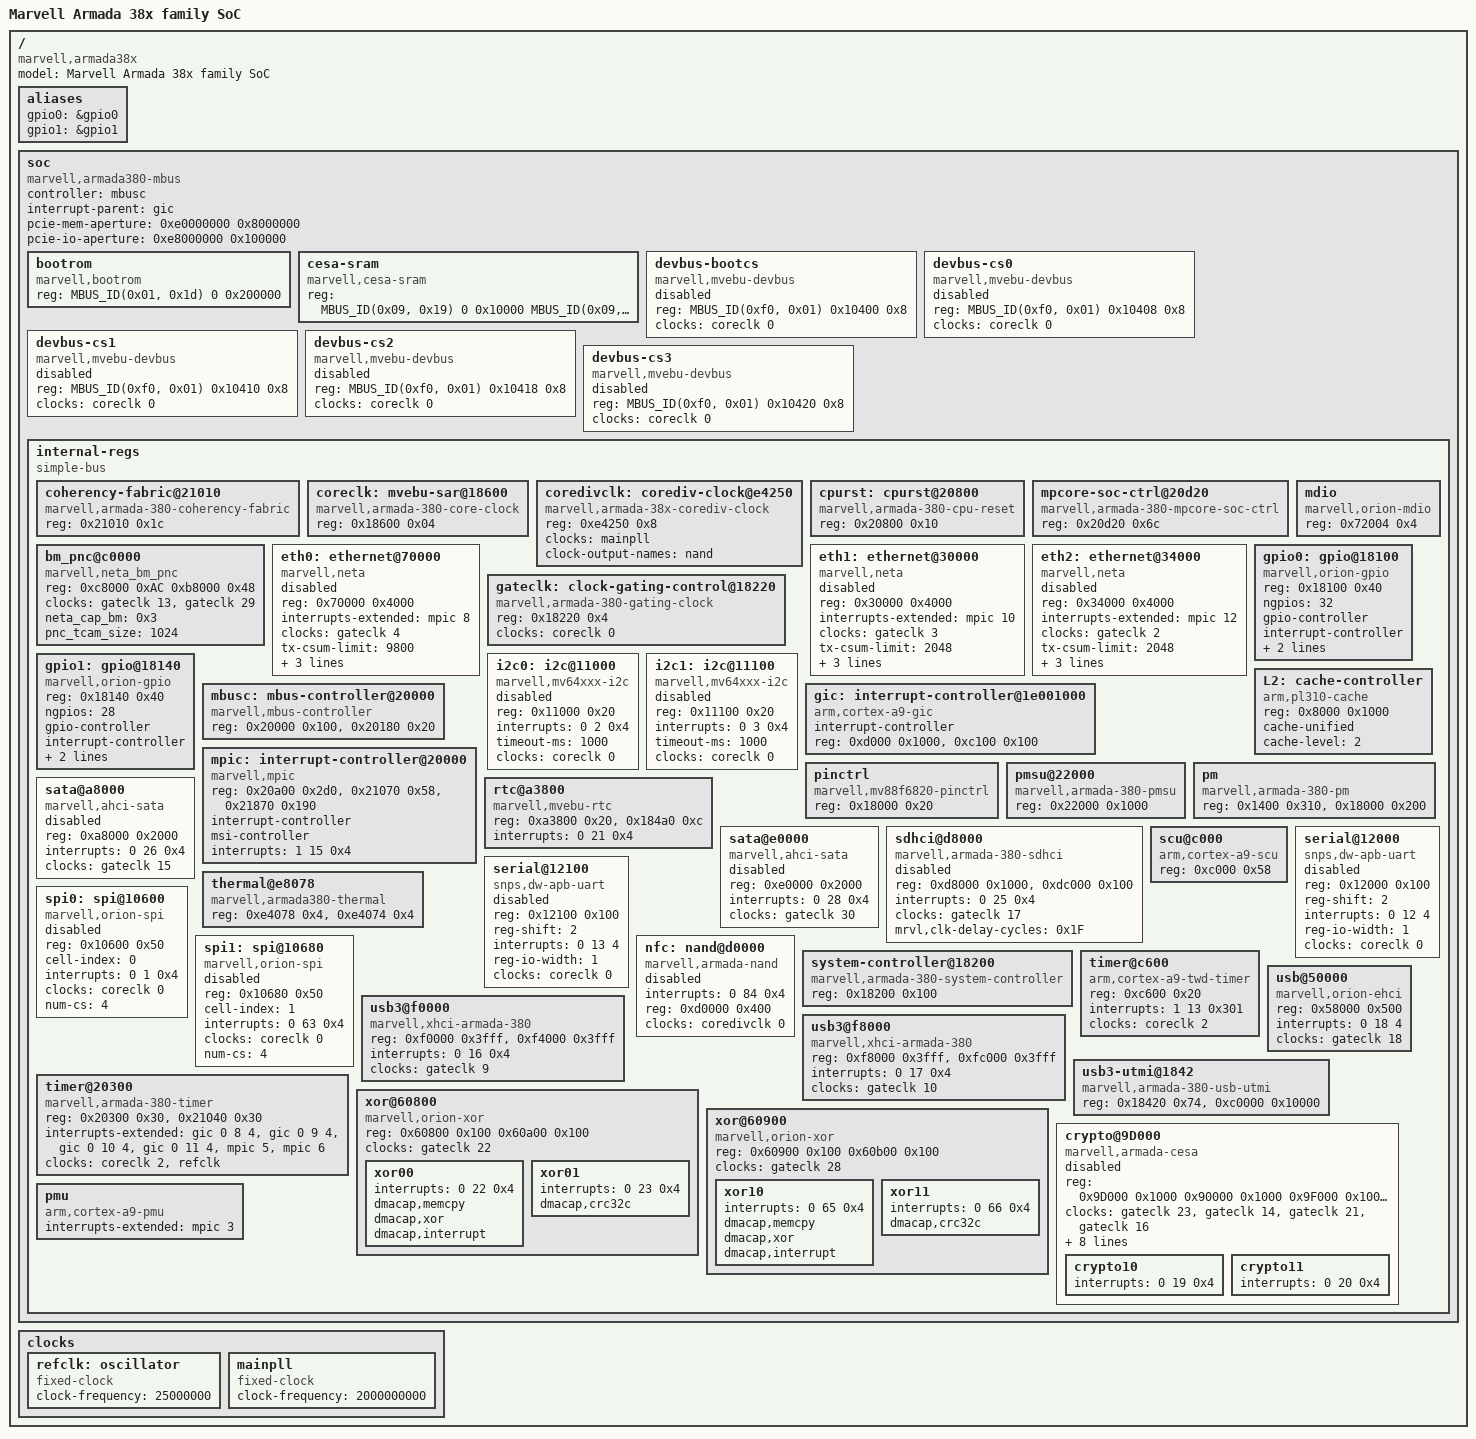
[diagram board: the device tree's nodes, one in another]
/*
 * Device Tree Include file for Marvell Armada 38x family of SoCs.
 *
 * Copyright (C) 2013 Marvell
 *
 * Lior Amsalem <alior@marvell.com>
 * Gregory CLEMENT <gregory.clement@free-electrons.com>
 * Thomas Petazzoni <thomas.petazzoni@free-electrons.com>
 *
 * This file is licensed under the terms of the GNU General Public
 * License version 2.  This program is licensed "as is" without any
 * warranty of any kind, whether express or implied.
 */

#include "skeleton.dtsi"

#define MBUS_ID(target,attributes) (((target) << 24) | ((attributes) << 16))

/ {
	model = "Marvell Armada 38x family SoC";
	compatible = "marvell,armada38x";

	aliases {
		gpio0 = &gpio0;
		gpio1 = &gpio1;
	};

	soc {
		compatible = "marvell,armada380-mbus", "simple-bus";
		#address-cells = <2>;
		#size-cells = <1>;
		controller = <&mbusc>;
		interrupt-parent = <&gic>;
		pcie-mem-aperture = <0xe0000000 0x8000000>;
		pcie-io-aperture  = <0xe8000000 0x100000>;

		ranges = <
			  MBUS_ID(0xf0, 0x01) 0 0xf1000000 0x100000
			  MBUS_ID(0x01, 0x1d) 0 0xfff00000 0x100000
			  MBUS_ID(0x09, 0x19) 0 0xf1100000 0x10000	/* CESA0: PHYS=0xf1100000
									   size 64K */
			  MBUS_ID(0x09, 0x15) 0 0xf1110000 0x10000	/* CESA1: PHYS=0xf1110000 */
			  MBUS_ID(0x0c, 0x04) 0 0xf1200000 0x100000	/* BM: PHYS=0xf1200000 size 1M */
			  MBUS_ID(0x0b, 0x04) 0 0xf1300000 0x100000>;	/* PNC: PHYS=0xf1300000 size 1M */

		bootrom {
			compatible = "marvell,bootrom";
			reg = <MBUS_ID(0x01, 0x1d) 0 0x200000>;
		};

		/* Security Accelerator SRAM (CESA) */
		cesa-sram {
			compatible = "marvell,cesa-sram";
			reg = <MBUS_ID(0x09, 0x19) 0 0x10000   /*chan0*/
			       MBUS_ID(0x09, 0x15) 0 0x10000>; /*chan1*/
		};

		devbus-bootcs {
			compatible = "marvell,mvebu-devbus";
			reg = <MBUS_ID(0xf0, 0x01) 0x10400 0x8>;
			ranges = <0 MBUS_ID(0x01, 0x2f) 0 0xffffffff>;
			#address-cells = <1>;
			#size-cells = <1>;
			clocks = <&coreclk 0>;
			status = "disabled";
		};

		devbus-cs0 {
			compatible = "marvell,mvebu-devbus";
			reg = <MBUS_ID(0xf0, 0x01) 0x10408 0x8>;
			ranges = <0 MBUS_ID(0x01, 0x3e) 0 0xffffffff>;
			#address-cells = <1>;
			#size-cells = <1>;
			clocks = <&coreclk 0>;
			status = "disabled";
		};

		devbus-cs1 {
			compatible = "marvell,mvebu-devbus";
			reg = <MBUS_ID(0xf0, 0x01) 0x10410 0x8>;
			ranges = <0 MBUS_ID(0x01, 0x3d) 0 0xffffffff>;
			#address-cells = <1>;
			#size-cells = <1>;
			clocks = <&coreclk 0>;
			status = "disabled";
		};

		devbus-cs2 {
			compatible = "marvell,mvebu-devbus";
			reg = <MBUS_ID(0xf0, 0x01) 0x10418 0x8>;
			ranges = <0 MBUS_ID(0x01, 0x3b) 0 0xffffffff>;
			#address-cells = <1>;
			#size-cells = <1>;
			clocks = <&coreclk 0>;
			status = "disabled";
		};

		devbus-cs3 {
			compatible = "marvell,mvebu-devbus";
			reg = <MBUS_ID(0xf0, 0x01) 0x10420 0x8>;
			ranges = <0 MBUS_ID(0x01, 0x37) 0 0xffffffff>;
			#address-cells = <1>;
			#size-cells = <1>;
			clocks = <&coreclk 0>;
			status = "disabled";
		};

		internal-regs {
			compatible = "simple-bus";
			#address-cells = <1>;
			#size-cells = <1>;
			ranges = <0 MBUS_ID(0xf0, 0x01) 0 0x100000>;

			coherency-fabric@21010 {
				compatible = "marvell,armada-380-coherency-fabric";
				reg = <0x21010 0x1c>;
			};

			coreclk: mvebu-sar@18600 {
				compatible = "marvell,armada-380-core-clock";
				reg = <0x18600 0x04>;
				#clock-cells = <1>;
			};

			coredivclk: corediv-clock@e4250 {
				compatible = "marvell,armada-38x-corediv-clock";
				reg = <0xe4250 0x8>;
				#clock-cells = <1>;
				clocks = <&mainpll>;
				clock-output-names = "nand";
			};

			cpurst: cpurst@20800 {
				compatible = "marvell,armada-380-cpu-reset";
				reg = <0x20800 0x10>;
				#reset-cells = <1>;
			};

			mpcore-soc-ctrl@20d20 {
				compatible = "marvell,armada-380-mpcore-soc-ctrl";
				reg = <0x20d20 0x6c>;
			};

			mdio {
				#address-cells = <1>;
				#size-cells = <0>;
				compatible = "marvell,orion-mdio";
				reg = <0x72004 0x4>;
			};

			/* PnC and BM */
			bm_pnc@c0000 {
				compatible = "marvell,neta_bm_pnc";
				reg = <0xc8000 0xAC 0xb8000 0x48>;
				clocks = <&gateclk 13>, <&gateclk 29>;
				/*neta_cap_bm, bitmap of NETA dynamic capabilities, such as PNC, BM, HWF and PME
				  PNC--0x1, BM--0x2, HWF--0x4, PME--0x8*/
				neta_cap_bm = <0x3>;
				pnc_tcam_size = <1024>;
			};

			eth0: ethernet@70000 {
				compatible = "marvell,neta";
				reg = <0x70000 0x4000>;
				interrupts-extended = <&mpic 8>;
				clocks = <&gateclk 4>;
				tx-csum-limit = <9800>;
				status = "disabled";
				mac-address = [ 00 50 43 02 02 01 ];
				eth,port-num    = <0>;
				eth,port-mtu    = <1500>;
			};

			eth1: ethernet@30000 {
				compatible = "marvell,neta";
				reg = <0x30000 0x4000>;
				interrupts-extended = <&mpic 10>;
				clocks = <&gateclk 3>;
				tx-csum-limit = <2048>;
				status = "disabled";
				mac-address = [ 00 50 43 02 02 02 ];
				eth,port-num    = <1>;
				eth,port-mtu    = <1500>;
			};

			eth2: ethernet@34000 {
				compatible = "marvell,neta";
				reg = <0x34000 0x4000>;
				interrupts-extended = <&mpic 12>;
				clocks = <&gateclk 2>;
				tx-csum-limit = <2048>;
				status = "disabled";
				mac-address = [ 00 50 43 02 02 03 ];
				eth,port-num    = <2>;
				eth,port-mtu    = <1500>;
			};

			gateclk: clock-gating-control@18220 {
				compatible = "marvell,armada-380-gating-clock";
				reg = <0x18220 0x4>;
				clocks = <&coreclk 0>;
				#clock-cells = <1>;
			};

			gpio0: gpio@18100 {
				compatible = "marvell,orion-gpio";
				reg = <0x18100 0x40>;
				ngpios = <32>;
				gpio-controller;
				#gpio-cells = <2>;
				interrupt-controller;
				#interrupt-cells = <2>;
				interrupts = <0 53 0x4>, <0 54 0x4>,
					     <0 55 0x4>, <0 56 0x4>;
			};

			gpio1: gpio@18140 {
				compatible = "marvell,orion-gpio";
				reg = <0x18140 0x40>;
				ngpios = <28>;
				gpio-controller;
				#gpio-cells = <2>;
				interrupt-controller;
				#interrupt-cells = <2>;
				interrupts = <0 58 0x4>, <0 59 0x4>,
					     <0 60 0x4>, <0 61 0x4>;
			};

			i2c0: i2c@11000 {
				compatible = "marvell,mv64xxx-i2c";
				reg = <0x11000 0x20>;
				#address-cells = <1>;
				#size-cells = <0>;
				interrupts = <0 2 0x4>;
				timeout-ms = <1000>;
				clocks = <&coreclk 0>;
				status = "disabled";
			};

			i2c1: i2c@11100 {
				compatible = "marvell,mv64xxx-i2c";
				reg = <0x11100 0x20>;
				#address-cells = <1>;
				#size-cells = <0>;
				interrupts = <0 3 0x4>;
				timeout-ms = <1000>;
				clocks = <&coreclk 0>;
				status = "disabled";
			};

			gic: interrupt-controller@1e001000 {
				compatible = "arm,cortex-a9-gic";
				#interrupt-cells = <3>;
				#size-cells = <0>;
				interrupt-controller;
				reg = <0xd000 0x1000>,
				      <0xc100 0x100>;
			};

			L2: cache-controller {
				compatible = "arm,pl310-cache";
				reg = <0x8000 0x1000>;
				cache-unified;
				cache-level = <2>;
			};

			mbusc: mbus-controller@20000 {
				compatible = "marvell,mbus-controller";
				reg = <0x20000 0x100>, <0x20180 0x20>;
			};

			mpic: interrupt-controller@20000 {
				compatible = "marvell,mpic";
				reg = <0x20a00 0x2d0>, <0x21070 0x58>, <0x21870 0x190>;
				#interrupt-cells = <1>;
				#size-cells = <1>;
				interrupt-controller;
				msi-controller;
				interrupts = <1 15 0x4>;
			};

			pinctrl {
				compatible = "marvell,mv88f6820-pinctrl";
				reg = <0x18000 0x20>;
			};

			pmsu@22000 {
				compatible = "marvell,armada-380-pmsu";
				reg = <0x22000 0x1000>;
			};

			pm {
				compatible = "marvell,armada-380-pm";
				reg = <0x1400 0x310>, <0x18000 0x200>;
			};

			rtc@a3800 {
				compatible = "marvell,mvebu-rtc";
				reg = <0xa3800 0x20>, <0x184a0 0xc>;
				interrupts = <0 21 0x4>;
			};

			sata@a8000 {
				compatible = "marvell,ahci-sata";
				reg = <0xa8000 0x2000>;
				interrupts = <0 26 0x4>;
				clocks = <&gateclk 15>;
				status = "disabled";
			};

			sata@e0000 {
				compatible = "marvell,ahci-sata";
				reg = <0xe0000 0x2000>;
				interrupts = <0 28 0x4>;
				clocks = <&gateclk 30>;
				status = "disabled";
			};

			sdhci@d8000 {
				compatible = "marvell,armada-380-sdhci";
				reg = <0xd8000 0x1000>, <0xdc000 0x100>;
				interrupts = <0 25 0x4>;
				clocks = <&gateclk 17>;
				mrvl,clk-delay-cycles = <0x1F>;
				status = "disabled";
			};

			scu@c000 {
				compatible = "arm,cortex-a9-scu";
				reg = <0xc000 0x58>;
			};

			serial@12000 {
				compatible = "snps,dw-apb-uart";
				reg = <0x12000 0x100>;
				reg-shift = <2>;
				interrupts = <0 12 4>;
				reg-io-width = <1>;
				clocks = <&coreclk 0>;
				status = "disabled";
			};

			serial@12100 {
				compatible = "snps,dw-apb-uart";
				reg = <0x12100 0x100>;
				reg-shift = <2>;
				interrupts = <0 13 4>;
				reg-io-width = <1>;
				clocks = <&coreclk 0>;
				status = "disabled";
			};

			thermal@e8078 {
				compatible = "marvell,armada380-thermal";
				reg = <0xe4078 0x4>, <0xe4074 0x4>;
				status = "okay";
			};

			spi0: spi@10600 {
				compatible = "marvell,orion-spi";
				reg = <0x10600 0x50>;
				#address-cells = <1>;
				#size-cells = <0>;
				cell-index = <0>;
				interrupts = <0 1 0x4>;
				clocks = <&coreclk 0>;
				num-cs = <4>;
				status = "disabled";
			};

			spi1: spi@10680 {
				compatible = "marvell,orion-spi";
				reg = <0x10680 0x50>;
				#address-cells = <1>;
				#size-cells = <0>;
				cell-index = <1>;
				interrupts = <0 63 0x4>;
				clocks = <&coreclk 0>;
				num-cs = <4>;
				status = "disabled";
			};

			nfc: nand@d0000 {
				compatible = "marvell,armada-nand";
				interrupts = <0 84 0x4>;
				reg = <0xd0000 0x400>;
				clocks = <&coredivclk 0>;
				clock-names = "ecc_clk";
				status = "disabled";
			};

			system-controller@18200 {
				compatible = "marvell,armada-380-system-controller";
				reg = <0x18200 0x100>;
			};

			timer@c600 {
				compatible = "arm,cortex-a9-twd-timer";
				reg = <0xc600 0x20>;
				interrupts = <1 13 0x301>;
				clocks = <&coreclk 2>;
			};

			usb@50000 {
				compatible = "marvell,orion-ehci";
				reg = <0x58000 0x500>;
				interrupts = <0 18 4>;
				clocks = <&gateclk 18>;
			};

			usb3@f0000 {
				compatible = "marvell,xhci-armada-380";
				reg = <0xf0000 0x3fff>,<0xf4000 0x3fff>;
				interrupts = <0 16 0x4>;
				clocks = <&gateclk 9>;
			};

			usb3@f8000 {
				compatible = "marvell,xhci-armada-380";
				reg = <0xf8000 0x3fff>,<0xfc000 0x3fff>;
				interrupts = <0 17 0x4>;
				clocks = <&gateclk 10>;
			};

			usb3-utmi@1842 {
				compatible = "marvell,armada-380-usb-utmi";
				reg = <0x18420 0x74>,<0xc0000 0x10000>;
			};

			timer@20300 {
				compatible = "marvell,armada-380-timer";
				reg = <0x20300 0x30>, <0x21040 0x30>;
				interrupts-extended = <&gic  0  8 4>,
						      <&gic  0  9 4>,
						      <&gic  0 10 4>,
						      <&gic  0 11 4>,
						      <&mpic 5>,
						      <&mpic 6>;
				clocks = <&coreclk 2>, <&refclk>;
				clock-names = "nbclk", "fixed";
			};

			xor@60800 {
				compatible = "marvell,orion-xor";
				reg = <0x60800 0x100
				       0x60a00 0x100>;
				clocks = <&gateclk 22>;
				status = "okay";

				xor00 {
					interrupts = <0 22 0x4>;
					dmacap,memcpy;
					dmacap,xor;
					dmacap,interrupt;
				};
				xor01 {
					interrupts = <0 23 0x4>;
					dmacap,crc32c;
				};
			};

			xor@60900 {
				compatible = "marvell,orion-xor";
				reg = <0x60900 0x100
				       0x60b00 0x100>;
				clocks = <&gateclk 28>;
				status = "okay";

				xor10 {
					interrupts = <0 65 0x4>;
					dmacap,memcpy;
					dmacap,xor;
					dmacap,interrupt;
				};
				xor11 {
					interrupts = <0 66 0x4>;
					dmacap,crc32c;
				};
			};

			crypto@9D000 {
				compatible = "marvell,armada-cesa";
				reg = <0x9D000 0x1000	/* cesa base reg chan 0 */
				       0x90000 0x1000	/* tdma base reg chan 0 */
				       0x9F000 0x1000	/* cesa base reg chan 1 */
				       0x92000 0x1000>;	/* tdma base reg chan 1 */
				clocks = <&gateclk 23>, <&gateclk 14>,
				         <&gateclk 21>, <&gateclk 16>;
				clock-names = "crypto0", "crypto0z",
					      "crypto1", "crypto1z";
				cesa,channels = <0x2>;
				cesa,mode = "ocf";	/* ocf or test */
				cesa,feature = "int_coalescing"; /* chain, int_coalescing
							   or int_per_packet */

				/* threshold and time_threshold relevant if
				   int_coalescing in use */
				cesa,threshold = <0x2>;
				cesa,time_threshold = <0xff>;

				cesa,ctrlModel = /bits/ 16 <0x6800>;
				cesa,ctrlRev = /bits/ 8 <2>;
				cesa,sramOffset = /bits/ 16 <0x40>;
				status = "disabled";

				crypto10 {
					/* channel 0 */
					interrupts = <0 19 0x4>;
				};
				crypto11 {
					/* channel 1 */
					interrupts = <0 20 0x4>;
				};
			};

			pmu {
				compatible = "arm,cortex-a9-pmu";
				interrupts-extended = <&mpic 3>;
			};
		};
	};

	clocks {
		/* 25 MHz reference crystal */
		refclk: oscillator {
			compatible = "fixed-clock";
			#clock-cells = <0>;
			clock-frequency = <25000000>;
		};
		/* 2 GHz fixed main PLL */
		mainpll: mainpll {
			compatible = "fixed-clock";
			#clock-cells = <0>;
			clock-frequency = <2000000000>;
		};
	};
};
